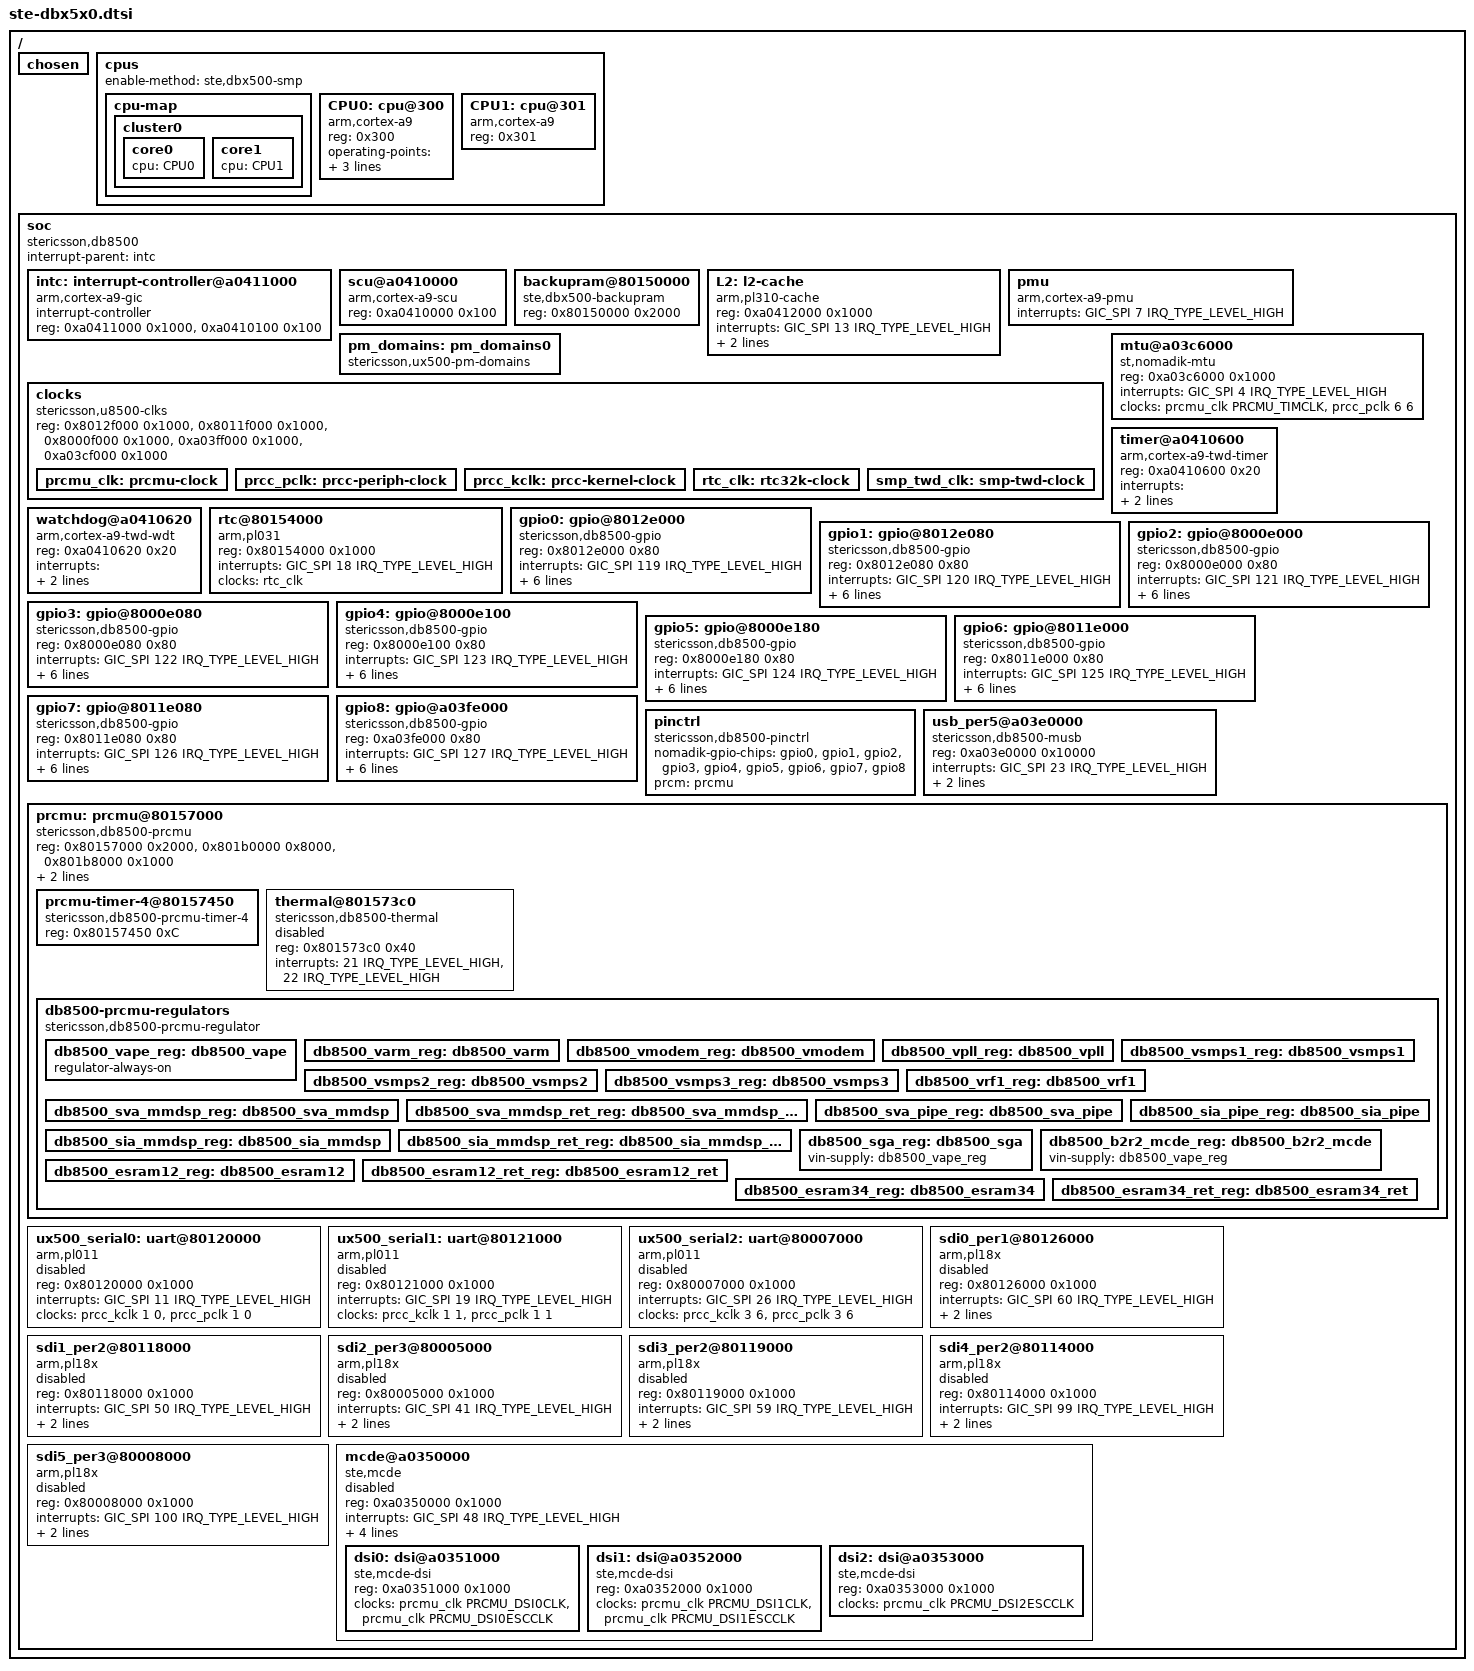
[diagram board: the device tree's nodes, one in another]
// SPDX-License-Identifier: GPL-2.0-or-later
/*
 * Copyright 2012 Linaro Ltd
 */

#include <dt-bindings/interrupt-controller/irq.h>
#include <dt-bindings/interrupt-controller/arm-gic.h>
#include <dt-bindings/mfd/dbx500-prcmu.h>
#include <dt-bindings/arm/ux500_pm_domains.h>
#include <dt-bindings/gpio/gpio.h>

/ {
	#address-cells = <1>;
	#size-cells = <1>;

	chosen {
	};

	cpus {
		#address-cells = <1>;
		#size-cells = <0>;
		enable-method = "ste,dbx500-smp";

		cpu-map {
			cluster0 {
				core0 {
					cpu = <&CPU0>;
				};
				core1 {
					cpu = <&CPU1>;
				};
			};
		};
		CPU0: cpu@300 {
			device_type = "cpu";
			compatible = "arm,cortex-a9";
			reg = <0x300>;
			/* cpufreq controls */
			operating-points = <998400 0
					    800000 0
					    400000 0
					    200000 0>;
			clocks = <&prcmu_clk PRCMU_ARMSS>;
			clock-names = "cpu";
			clock-latency = <20000>;
		};
		CPU1: cpu@301 {
			device_type = "cpu";
			compatible = "arm,cortex-a9";
			reg = <0x301>;
		};
	};

	soc {
		#address-cells = <1>;
		#size-cells = <1>;
		compatible = "stericsson,db8500", "simple-bus";
		interrupt-parent = <&intc>;
		ranges;

		intc: interrupt-controller@a0411000 {
			compatible = "arm,cortex-a9-gic";
			#interrupt-cells = <3>;
			#address-cells = <1>;
			interrupt-controller;
			reg = <0xa0411000 0x1000>,
			      <0xa0410100 0x100>;
		};

		scu@a0410000 {
			compatible = "arm,cortex-a9-scu";
			reg = <0xa0410000 0x100>;
		};

		/*
		 * The backup RAM is used for retention during sleep
		 * and various things like spin tables
		 */
		backupram@80150000 {
			compatible = "ste,dbx500-backupram";
			reg = <0x80150000 0x2000>;
		};

		L2: l2-cache {
			compatible = "arm,pl310-cache";
			reg = <0xa0412000 0x1000>;
			interrupts = <GIC_SPI 13 IRQ_TYPE_LEVEL_HIGH>;
			cache-unified;
			cache-level = <2>;
		};

		pmu {
			compatible = "arm,cortex-a9-pmu";
			interrupts = <GIC_SPI 7 IRQ_TYPE_LEVEL_HIGH>;
		};

		pm_domains: pm_domains0 {
			compatible = "stericsson,ux500-pm-domains";
			#power-domain-cells = <1>;
		};

		clocks {
			compatible = "stericsson,u8500-clks";
			/*
			 * Registers for the CLKRST block on peripheral
			 * groups 1, 2, 3, 5, 6,
			 */
			reg = <0x8012f000 0x1000>, <0x8011f000 0x1000>,
			    <0x8000f000 0x1000>, <0xa03ff000 0x1000>,
			    <0xa03cf000 0x1000>;

			prcmu_clk: prcmu-clock {
				#clock-cells = <1>;
			};

			prcc_pclk: prcc-periph-clock {
				#clock-cells = <2>;
			};

			prcc_kclk: prcc-kernel-clock {
				#clock-cells = <2>;
			};

			rtc_clk: rtc32k-clock {
				#clock-cells = <0>;
			};

			smp_twd_clk: smp-twd-clock {
				#clock-cells = <0>;
			};
		};

		mtu@a03c6000 {
			/* Nomadik System Timer */
			compatible = "st,nomadik-mtu";
			reg = <0xa03c6000 0x1000>;
			interrupts = <GIC_SPI 4 IRQ_TYPE_LEVEL_HIGH>;

			clocks = <&prcmu_clk PRCMU_TIMCLK>, <&prcc_pclk 6 6>;
			clock-names = "timclk", "apb_pclk";
		};

		timer@a0410600 {
			compatible = "arm,cortex-a9-twd-timer";
			reg = <0xa0410600 0x20>;
			interrupts = <GIC_PPI 13 (GIC_CPU_MASK_RAW(3) | IRQ_TYPE_LEVEL_HIGH)>;

			clocks = <&smp_twd_clk>;
		};

		watchdog@a0410620 {
			compatible = "arm,cortex-a9-twd-wdt";
			reg = <0xa0410620 0x20>;
			interrupts = <GIC_PPI 14 (GIC_CPU_MASK_RAW(3) | IRQ_TYPE_LEVEL_HIGH)>;
			clocks = <&smp_twd_clk>;
		};

		rtc@80154000 {
			compatible = "arm,pl031", "arm,primecell";
			reg = <0x80154000 0x1000>;
			interrupts = <GIC_SPI 18 IRQ_TYPE_LEVEL_HIGH>;

			clocks = <&rtc_clk>;
			clock-names = "apb_pclk";
		};

		gpio0: gpio@8012e000 {
			compatible = "stericsson,db8500-gpio",
				"st,nomadik-gpio";
			reg =  <0x8012e000 0x80>;
			interrupts = <GIC_SPI 119 IRQ_TYPE_LEVEL_HIGH>;
			interrupt-controller;
			#interrupt-cells = <2>;
			st,supports-sleepmode;
			gpio-controller;
			#gpio-cells = <2>;
			gpio-bank = <0>;
			gpio-ranges = <&pinctrl 0 0 32>;
			clocks = <&prcc_pclk 1 9>;
		};

		gpio1: gpio@8012e080 {
			compatible = "stericsson,db8500-gpio",
				"st,nomadik-gpio";
			reg =  <0x8012e080 0x80>;
			interrupts = <GIC_SPI 120 IRQ_TYPE_LEVEL_HIGH>;
			interrupt-controller;
			#interrupt-cells = <2>;
			st,supports-sleepmode;
			gpio-controller;
			#gpio-cells = <2>;
			gpio-bank = <1>;
			gpio-ranges = <&pinctrl 0 32 5>;
			clocks = <&prcc_pclk 1 9>;
		};

		gpio2: gpio@8000e000 {
			compatible = "stericsson,db8500-gpio",
				"st,nomadik-gpio";
			reg =  <0x8000e000 0x80>;
			interrupts = <GIC_SPI 121 IRQ_TYPE_LEVEL_HIGH>;
			interrupt-controller;
			#interrupt-cells = <2>;
			st,supports-sleepmode;
			gpio-controller;
			#gpio-cells = <2>;
			gpio-bank = <2>;
			gpio-ranges = <&pinctrl 0 64 32>;
			clocks = <&prcc_pclk 3 8>;
		};

		gpio3: gpio@8000e080 {
			compatible = "stericsson,db8500-gpio",
				"st,nomadik-gpio";
			reg =  <0x8000e080 0x80>;
			interrupts = <GIC_SPI 122 IRQ_TYPE_LEVEL_HIGH>;
			interrupt-controller;
			#interrupt-cells = <2>;
			st,supports-sleepmode;
			gpio-controller;
			#gpio-cells = <2>;
			gpio-bank = <3>;
			gpio-ranges = <&pinctrl 0 96 2>;
			clocks = <&prcc_pclk 3 8>;
		};

		gpio4: gpio@8000e100 {
			compatible = "stericsson,db8500-gpio",
				"st,nomadik-gpio";
			reg =  <0x8000e100 0x80>;
			interrupts = <GIC_SPI 123 IRQ_TYPE_LEVEL_HIGH>;
			interrupt-controller;
			#interrupt-cells = <2>;
			st,supports-sleepmode;
			gpio-controller;
			#gpio-cells = <2>;
			gpio-bank = <4>;
			gpio-ranges = <&pinctrl 0 128 32>;
			clocks = <&prcc_pclk 3 8>;
		};

		gpio5: gpio@8000e180 {
			compatible = "stericsson,db8500-gpio",
				"st,nomadik-gpio";
			reg =  <0x8000e180 0x80>;
			interrupts = <GIC_SPI 124 IRQ_TYPE_LEVEL_HIGH>;
			interrupt-controller;
			#interrupt-cells = <2>;
			st,supports-sleepmode;
			gpio-controller;
			#gpio-cells = <2>;
			gpio-bank = <5>;
			gpio-ranges = <&pinctrl 0 160 12>;
			clocks = <&prcc_pclk 3 8>;
		};

		gpio6: gpio@8011e000 {
			compatible = "stericsson,db8500-gpio",
				"st,nomadik-gpio";
			reg =  <0x8011e000 0x80>;
			interrupts = <GIC_SPI 125 IRQ_TYPE_LEVEL_HIGH>;
			interrupt-controller;
			#interrupt-cells = <2>;
			st,supports-sleepmode;
			gpio-controller;
			#gpio-cells = <2>;
			gpio-bank = <6>;
			gpio-ranges = <&pinctrl 0 192 32>;
			clocks = <&prcc_pclk 2 11>;
		};

		gpio7: gpio@8011e080 {
			compatible = "stericsson,db8500-gpio",
				"st,nomadik-gpio";
			reg =  <0x8011e080 0x80>;
			interrupts = <GIC_SPI 126 IRQ_TYPE_LEVEL_HIGH>;
			interrupt-controller;
			#interrupt-cells = <2>;
			st,supports-sleepmode;
			gpio-controller;
			#gpio-cells = <2>;
			gpio-bank = <7>;
			gpio-ranges = <&pinctrl 0 224 7>;
			clocks = <&prcc_pclk 2 11>;
		};

		gpio8: gpio@a03fe000 {
			compatible = "stericsson,db8500-gpio",
				"st,nomadik-gpio";
			reg =  <0xa03fe000 0x80>;
			interrupts = <GIC_SPI 127 IRQ_TYPE_LEVEL_HIGH>;
			interrupt-controller;
			#interrupt-cells = <2>;
			st,supports-sleepmode;
			gpio-controller;
			#gpio-cells = <2>;
			gpio-bank = <8>;
			gpio-ranges = <&pinctrl 0 256 12>;
			clocks = <&prcc_pclk 5 1>;
		};

		pinctrl: pinctrl {
			compatible = "stericsson,db8500-pinctrl";
			nomadik-gpio-chips = <&gpio0>, <&gpio1>, <&gpio2>, <&gpio3>,
						<&gpio4>, <&gpio5>, <&gpio6>, <&gpio7>,
						<&gpio8>;
			prcm = <&prcmu>;
		};

		usb_per5@a03e0000 {
			compatible = "stericsson,db8500-musb";
			reg = <0xa03e0000 0x10000>;
			interrupts = <GIC_SPI 23 IRQ_TYPE_LEVEL_HIGH>;
			interrupt-names = "mc";

			dr_mode = "otg";

			clocks = <&prcc_pclk 5 0>;
		};

		prcmu: prcmu@80157000 {
			compatible = "stericsson,db8500-prcmu", "syscon";
			reg = <0x80157000 0x2000>, <0x801b0000 0x8000>, <0x801b8000 0x1000>;
			reg-names = "prcmu", "prcmu-tcpm", "prcmu-tcdm";
			interrupts = <GIC_SPI 47 IRQ_TYPE_LEVEL_HIGH>;
			#address-cells = <1>;
			#size-cells = <1>;
			interrupt-controller;
			#interrupt-cells = <2>;
			ranges;

			prcmu-timer-4@80157450 {
				compatible = "stericsson,db8500-prcmu-timer-4";
				reg = <0x80157450 0xC>;
			};

			thermal@801573c0 {
				compatible = "stericsson,db8500-thermal";
				reg = <0x801573c0 0x40>;
				interrupts = <21 IRQ_TYPE_LEVEL_HIGH>,
					     <22 IRQ_TYPE_LEVEL_HIGH>;
				interrupt-names = "IRQ_HOTMON_LOW", "IRQ_HOTMON_HIGH";
				status = "disabled";
			};

			db8500-prcmu-regulators {
				compatible = "stericsson,db8500-prcmu-regulator";

				// DB8500_REGULATOR_VAPE
				db8500_vape_reg: db8500_vape {
					regulator-always-on;
				};

				// DB8500_REGULATOR_VARM
				db8500_varm_reg: db8500_varm {
				};

				// DB8500_REGULATOR_VMODEM
				db8500_vmodem_reg: db8500_vmodem {
				};

				// DB8500_REGULATOR_VPLL
				db8500_vpll_reg: db8500_vpll {
				};

				// DB8500_REGULATOR_VSMPS1
				db8500_vsmps1_reg: db8500_vsmps1 {
				};

				// DB8500_REGULATOR_VSMPS2
				db8500_vsmps2_reg: db8500_vsmps2 {
				};

				// DB8500_REGULATOR_VSMPS3
				db8500_vsmps3_reg: db8500_vsmps3 {
				};

				// DB8500_REGULATOR_VRF1
				db8500_vrf1_reg: db8500_vrf1 {
				};

				// DB8500_REGULATOR_SWITCH_SVAMMDSP
				db8500_sva_mmdsp_reg: db8500_sva_mmdsp {
				};

				// DB8500_REGULATOR_SWITCH_SVAMMDSPRET
				db8500_sva_mmdsp_ret_reg: db8500_sva_mmdsp_ret {
				};

				// DB8500_REGULATOR_SWITCH_SVAPIPE
				db8500_sva_pipe_reg: db8500_sva_pipe {
				};

				// DB8500_REGULATOR_SWITCH_SIAMMDSP
				db8500_sia_mmdsp_reg: db8500_sia_mmdsp {
				};

				// DB8500_REGULATOR_SWITCH_SIAMMDSPRET
				db8500_sia_mmdsp_ret_reg: db8500_sia_mmdsp_ret {
				};

				// DB8500_REGULATOR_SWITCH_SIAPIPE
				db8500_sia_pipe_reg: db8500_sia_pipe {
				};

				// DB8500_REGULATOR_SWITCH_SGA
				db8500_sga_reg: db8500_sga {
					vin-supply = <&db8500_vape_reg>;
				};

				// DB8500_REGULATOR_SWITCH_B2R2_MCDE
				db8500_b2r2_mcde_reg: db8500_b2r2_mcde {
					vin-supply = <&db8500_vape_reg>;
				};

				// DB8500_REGULATOR_SWITCH_ESRAM12
				db8500_esram12_reg: db8500_esram12 {
				};

				// DB8500_REGULATOR_SWITCH_ESRAM12RET
				db8500_esram12_ret_reg: db8500_esram12_ret {
				};

				// DB8500_REGULATOR_SWITCH_ESRAM34
				db8500_esram34_reg: db8500_esram34 {
				};

				// DB8500_REGULATOR_SWITCH_ESRAM34RET
				db8500_esram34_ret_reg: db8500_esram34_ret {
				};
			};
		};

		ux500_serial0: uart@80120000 {
			compatible = "arm,pl011", "arm,primecell";
			reg = <0x80120000 0x1000>;
			interrupts = <GIC_SPI 11 IRQ_TYPE_LEVEL_HIGH>;

			clocks = <&prcc_kclk 1 0>, <&prcc_pclk 1 0>;
			clock-names = "uart", "apb_pclk";

			status = "disabled";
		};

		ux500_serial1: uart@80121000 {
			compatible = "arm,pl011", "arm,primecell";
			reg = <0x80121000 0x1000>;
			interrupts = <GIC_SPI 19 IRQ_TYPE_LEVEL_HIGH>;

			clocks = <&prcc_kclk 1 1>, <&prcc_pclk 1 1>;
			clock-names = "uart", "apb_pclk";

			status = "disabled";
		};

		ux500_serial2: uart@80007000 {
			compatible = "arm,pl011", "arm,primecell";
			reg = <0x80007000 0x1000>;
			interrupts = <GIC_SPI 26 IRQ_TYPE_LEVEL_HIGH>;

			clocks = <&prcc_kclk 3 6>, <&prcc_pclk 3 6>;
			clock-names = "uart", "apb_pclk";

			status = "disabled";
		};

		sdi0_per1@80126000 {
			compatible = "arm,pl18x", "arm,primecell";
			reg = <0x80126000 0x1000>;
			interrupts = <GIC_SPI 60 IRQ_TYPE_LEVEL_HIGH>;

			clocks = <&prcc_kclk 1 5>, <&prcc_pclk 1 5>;
			clock-names = "sdi", "apb_pclk";
			power-domains = <&pm_domains DOMAIN_VAPE>;

			status = "disabled";
		};

		sdi1_per2@80118000 {
			compatible = "arm,pl18x", "arm,primecell";
			reg = <0x80118000 0x1000>;
			interrupts = <GIC_SPI 50 IRQ_TYPE_LEVEL_HIGH>;

			clocks = <&prcc_kclk 2 4>, <&prcc_pclk 2 6>;
			clock-names = "sdi", "apb_pclk";
			power-domains = <&pm_domains DOMAIN_VAPE>;

			status = "disabled";
		};

		sdi2_per3@80005000 {
			compatible = "arm,pl18x", "arm,primecell";
			reg = <0x80005000 0x1000>;
			interrupts = <GIC_SPI 41 IRQ_TYPE_LEVEL_HIGH>;

			clocks = <&prcc_kclk 3 4>, <&prcc_pclk 3 4>;
			clock-names = "sdi", "apb_pclk";
			power-domains = <&pm_domains DOMAIN_VAPE>;

			status = "disabled";
		};

		sdi3_per2@80119000 {
			compatible = "arm,pl18x", "arm,primecell";
			reg = <0x80119000 0x1000>;
			interrupts = <GIC_SPI 59 IRQ_TYPE_LEVEL_HIGH>;

			clocks = <&prcc_kclk 2 5>, <&prcc_pclk 2 7>;
			clock-names = "sdi", "apb_pclk";
			power-domains = <&pm_domains DOMAIN_VAPE>;

			status = "disabled";
		};

		sdi4_per2@80114000 {
			compatible = "arm,pl18x", "arm,primecell";
			reg = <0x80114000 0x1000>;
			interrupts = <GIC_SPI 99 IRQ_TYPE_LEVEL_HIGH>;

			clocks = <&prcc_kclk 2 2>, <&prcc_pclk 2 4>;
			clock-names = "sdi", "apb_pclk";
			power-domains = <&pm_domains DOMAIN_VAPE>;

			status = "disabled";
		};

		sdi5_per3@80008000 {
			compatible = "arm,pl18x", "arm,primecell";
			reg = <0x80008000 0x1000>;
			interrupts = <GIC_SPI 100 IRQ_TYPE_LEVEL_HIGH>;

			clocks = <&prcc_kclk 3 7>, <&prcc_pclk 3 7>;
			clock-names = "sdi", "apb_pclk";
			power-domains = <&pm_domains DOMAIN_VAPE>;

			status = "disabled";
		};

		mcde@a0350000 {
			compatible = "ste,mcde";
			reg = <0xa0350000 0x1000>;
			interrupts = <GIC_SPI 48 IRQ_TYPE_LEVEL_HIGH>;
			epod-supply = <&db8500_b2r2_mcde_reg>;
			clocks = <&prcmu_clk PRCMU_MCDECLK>, /* Main MCDE clock */
				 <&prcmu_clk PRCMU_LCDCLK>, /* LCD clock */
				 <&prcmu_clk PRCMU_PLLDSI>; /* HDMI clock */
			clock-names = "mcde", "lcd", "hdmi";
			#address-cells = <1>;
			#size-cells = <1>;
			ranges;
			status = "disabled";

			dsi0: dsi@a0351000 {
				compatible = "ste,mcde-dsi";
				reg = <0xa0351000 0x1000>;
				clocks = <&prcmu_clk PRCMU_DSI0CLK>, <&prcmu_clk PRCMU_DSI0ESCCLK>;
				clock-names = "hs", "lp";
				#address-cells = <1>;
				#size-cells = <0>;
			};
			dsi1: dsi@a0352000 {
				compatible = "ste,mcde-dsi";
				reg = <0xa0352000 0x1000>;
				clocks = <&prcmu_clk PRCMU_DSI1CLK>, <&prcmu_clk PRCMU_DSI1ESCCLK>;
				clock-names = "hs", "lp";
				#address-cells = <1>;
				#size-cells = <0>;
			};
			dsi2: dsi@a0353000 {
				compatible = "ste,mcde-dsi";
				reg = <0xa0353000 0x1000>;
				/* This DSI port only has the Low Power / Energy Save clock */
				clocks = <&prcmu_clk PRCMU_DSI2ESCCLK>;
				clock-names = "lp";
				#address-cells = <1>;
				#size-cells = <0>;
			};
		};
	};
};
